CM_ "AUTOGENERATED FILE, DO NOT EDIT";

CM_ "Imported file _community.dbc starts here";
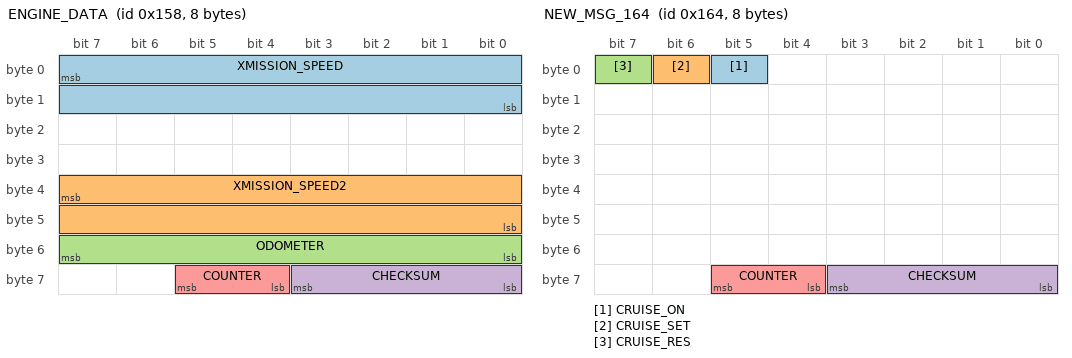
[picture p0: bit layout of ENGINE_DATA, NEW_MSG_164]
BO_ 344 ENGINE_DATA: 8 PCM
 SG_ XMISSION_SPEED : 7|16@0+ (0.01,0) [0|250] "kph" EON
 SG_ XMISSION_SPEED2 : 39|16@0+ (0.01,0) [0|250] "kph" EON
 SG_ ODOMETER : 55|8@0+ (10,0) [0|2550] "m" XXX
 SG_ CHECKSUM : 59|4@0+ (1,0) [0|15] "" EON
 SG_ COUNTER : 61|2@0+ (1,0) [0|3] "" EON

BO_ 356 NEW_MSG_164: 8 XXX
 SG_ CRUISE_ON : 5|1@0+ (1,0) [0|1] "" XXX
 SG_ CRUISE_SET : 6|1@0+ (1,0) [0|1] "" XXX
 SG_ CRUISE_RES : 7|1@0+ (1,0) [0|1] "" XXX
 SG_ CHECKSUM : 59|4@0+ (1,0) [0|15] "" XXX
 SG_ COUNTER : 60|2@1+ (1,0) [0|3] "" XXX

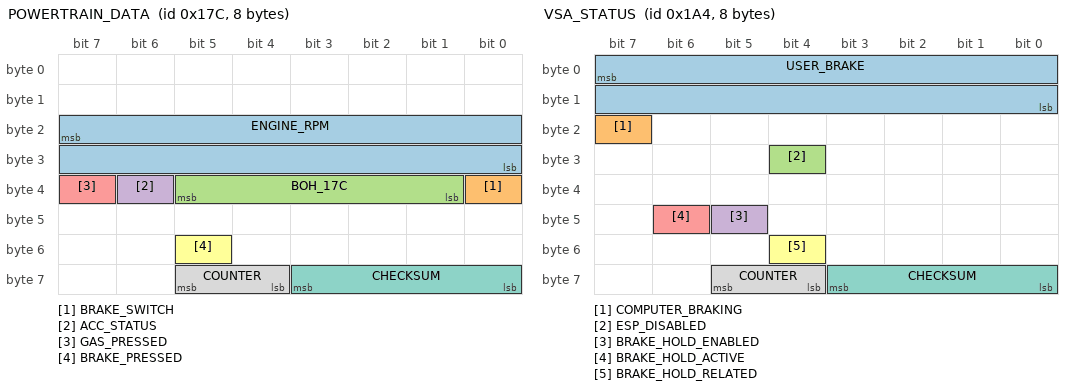
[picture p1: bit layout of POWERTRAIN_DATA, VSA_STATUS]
BO_ 380 POWERTRAIN_DATA: 8 PCM
 SG_ ENGINE_RPM : 23|16@0+ (1,0) [0|15000] "rpm" EON
 SG_ BRAKE_SWITCH : 32|1@0+ (1,0) [0|1] "" EON
 SG_ BOH_17C : 37|5@0+ (1,0) [0|1] "" EON
 SG_ ACC_STATUS : 38|1@0+ (1,0) [0|1] "" EON
 SG_ GAS_PRESSED : 39|1@0+ (1,0) [0|1] "" EON
 SG_ BRAKE_PRESSED : 53|1@0+ (1,0) [0|1] "" EON
 SG_ CHECKSUM : 59|4@0+ (1,0) [0|15] "" EON
 SG_ COUNTER : 61|2@0+ (1,0) [0|3] "" EON

BO_ 398 STEERING_EPS_DATA: 3 XXX
 SG_ NEW_SIGNAL_1 : 1|10@0+ (1,0) [0|1023] "" XXX
 SG_ COUNTER : 20|2@1+ (1,0) [0|3] "" XXX

BO_ 420 VSA_STATUS: 8 VSA
 SG_ USER_BRAKE : 7|16@0+ (0.015625,-1.609375) [0|1000] "" EON
 SG_ COMPUTER_BRAKING : 23|1@0+ (1,0) [0|1] "" EON
 SG_ ESP_DISABLED : 28|1@0+ (1,0) [0|1] "" EON
 SG_ BRAKE_HOLD_ENABLED : 45|1@0+ (1,0) [0|1] "" EON
 SG_ BRAKE_HOLD_ACTIVE : 46|1@0+ (1,0) [0|1] "" EON
 SG_ BRAKE_HOLD_RELATED : 52|1@0+ (1,0) [0|1] "" XXX
 SG_ CHECKSUM : 59|4@0+ (1,0) [0|15] "" EON
 SG_ COUNTER : 61|2@0+ (1,0) [0|3] "" EON

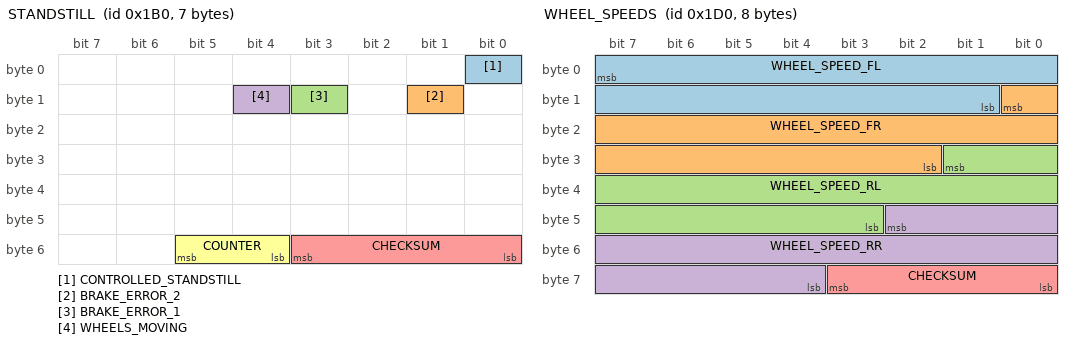
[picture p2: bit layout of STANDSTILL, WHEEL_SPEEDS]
BO_ 432 STANDSTILL: 7 VSA
 SG_ CONTROLLED_STANDSTILL : 0|1@0+ (1,0) [0|1] "" EON
 SG_ BRAKE_ERROR_2 : 9|1@0+ (1,0) [0|1] "" EON
 SG_ BRAKE_ERROR_1 : 11|1@0+ (1,0) [0|1] "" EON
 SG_ WHEELS_MOVING : 12|1@0+ (1,0) [0|1] "" EON
 SG_ CHECKSUM : 51|4@0+ (1,0) [0|3] "" EON
 SG_ COUNTER : 53|2@0+ (1,0) [0|3] "" EON

BO_ 464 WHEEL_SPEEDS: 8 VSA
 SG_ WHEEL_SPEED_FL : 7|15@0+ (0.01,0) [0|250] "kph" EON
 SG_ WHEEL_SPEED_FR : 8|15@0+ (0.01,0) [0|250] "kph" EON
 SG_ WHEEL_SPEED_RL : 25|15@0+ (0.01,0) [0|250] "kph" EON
 SG_ WHEEL_SPEED_RR : 42|15@0+ (0.01,0) [0|250] "kph" EON
 SG_ CHECKSUM : 59|4@0+ (1,0) [0|3] "" EON

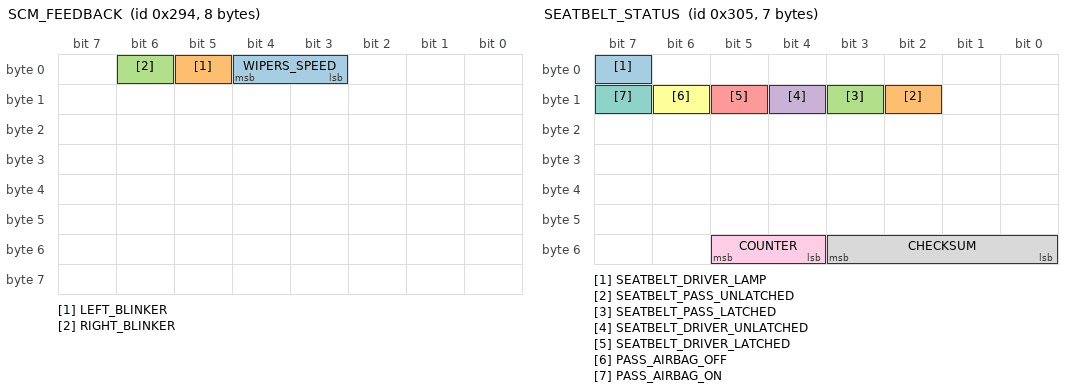
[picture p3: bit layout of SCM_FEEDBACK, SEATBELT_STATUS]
BO_ 660 SCM_FEEDBACK: 8 SCM
 SG_ WIPERS_SPEED : 4|2@0+ (1,0) [0|3] "" EON
 SG_ LEFT_BLINKER : 5|1@0+ (1,0) [0|1] "" EON
 SG_ RIGHT_BLINKER : 6|1@0+ (1,0) [0|1] "" EON

BO_ 773 SEATBELT_STATUS: 7 BDY
 SG_ SEATBELT_DRIVER_LAMP : 7|1@0+ (1,0) [0|1] "" EON
 SG_ SEATBELT_PASS_UNLATCHED : 10|1@0+ (1,0) [0|1] "" EON
 SG_ SEATBELT_PASS_LATCHED : 11|1@0+ (1,0) [0|1] "" EON
 SG_ SEATBELT_DRIVER_UNLATCHED : 12|1@0+ (1,0) [0|1] "" EON
 SG_ SEATBELT_DRIVER_LATCHED : 13|1@0+ (1,0) [0|1] "" EON
 SG_ PASS_AIRBAG_OFF : 14|1@0+ (1,0) [0|1] "" EON
 SG_ PASS_AIRBAG_ON : 15|1@0+ (1,0) [0|1] "" EON
 SG_ CHECKSUM : 51|4@0+ (1,0) [0|3] "" EON
 SG_ COUNTER : 53|2@0+ (1,0) [0|3] "" EON

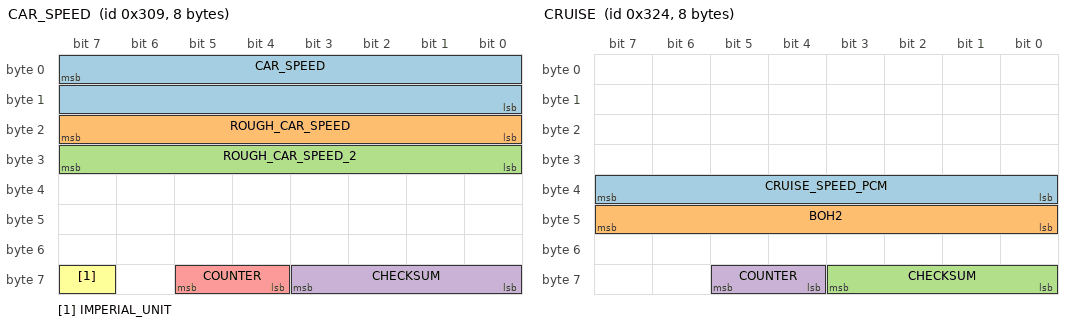
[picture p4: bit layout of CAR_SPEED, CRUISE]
BO_ 777 CAR_SPEED: 8 PCM
 SG_ CAR_SPEED : 7|16@0+ (0.01,0) [0|65535] "kph" XXX
 SG_ ROUGH_CAR_SPEED : 23|8@0+ (1,0) [0|255] "kph" XXX
 SG_ ROUGH_CAR_SPEED_2 : 31|8@0+ (1,0) [0|255] "kph" XXX
 SG_ CHECKSUM : 59|4@0+ (1,0) [0|15] "" XXX
 SG_ COUNTER : 61|2@0+ (1,0) [0|3] "" XXX
 SG_ IMPERIAL_UNIT : 63|1@0+ (1,0) [0|1] "" XXX

BO_ 804 CRUISE: 8 PCM
 SG_ CRUISE_SPEED_PCM : 39|8@0+ (1,0) [0|255] "" EON
 SG_ BOH2 : 47|8@0- (1,0) [0|255] "" EON
 SG_ CHECKSUM : 59|4@0+ (1,0) [0|15] "" EON
 SG_ COUNTER : 61|2@0+ (1,0) [0|3] "" EON

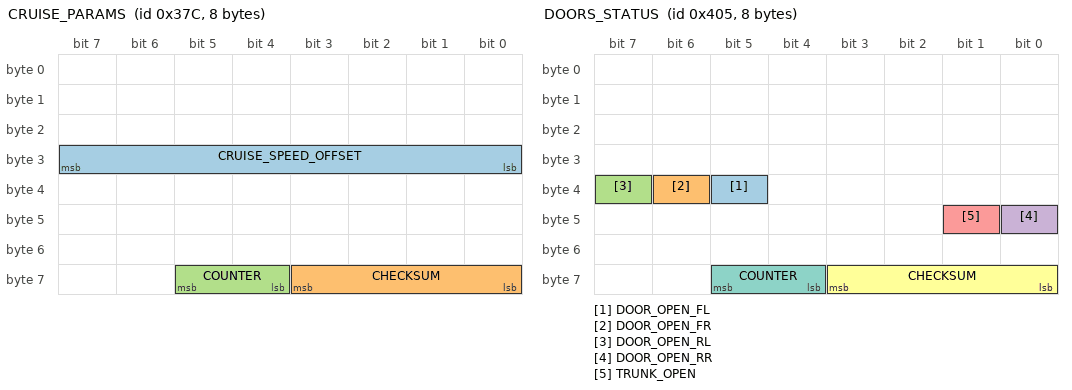
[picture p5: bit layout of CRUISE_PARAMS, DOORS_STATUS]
BO_ 892 CRUISE_PARAMS: 8 PCM
 SG_ CRUISE_SPEED_OFFSET : 31|8@0- (0.1,0) [-128|127] "kph" EON
 SG_ CHECKSUM : 59|4@0+ (1,0) [0|3] "" EON
 SG_ COUNTER : 61|2@0+ (1,0) [0|3] "" EON

BO_ 1029 DOORS_STATUS: 8 BDY
 SG_ DOOR_OPEN_FL : 37|1@0+ (1,0) [0|1] "" EON
 SG_ DOOR_OPEN_FR : 38|1@0+ (1,0) [0|1] "" EON
 SG_ DOOR_OPEN_RL : 39|1@0+ (1,0) [0|1] "" EON
 SG_ DOOR_OPEN_RR : 40|1@0+ (1,0) [0|1] "" EON
 SG_ TRUNK_OPEN : 41|1@0+ (1,0) [0|1] "" EON
 SG_ CHECKSUM : 59|4@0+ (1,0) [0|15] "" EON
 SG_ COUNTER : 61|2@0+ (1,0) [0|3] "" EON

CM_ SG_ 420 BRAKE_HOLD_RELATED "On when Brake Hold engaged";
CM_ SG_ 773 PASS_AIRBAG_OFF "Might just be indicator light";
CM_ SG_ 773 PASS_AIRBAG_ON "Might just be indicator light";
CM_ SG_ 804 CRUISE_SPEED_PCM "255 = no speed";
